# nrf7120E_enga_application register map
Vendor: Nordic Semiconductor; Series: nrf71; File version: 1
CPU: CM33 r0p4, little endian, MPU, FPU, 3 interrupt priority bits, 270 interrupts, 4 SAU regions
Registers are 32-bit, read-write, reset 0x0 unless marked. A register's access mark holds for its fields unless they carry their own. Offsets are from the block's base; [hi:lo] are bit positions; lines under a group give offsets from that group; {n}, {i} and the like mark numbered series; 'fields as' and 'values as' point back to an identical list.

## BELLBOARD_NS — BELLBOARD APB registers
Base 0x40078000
{0x0+4i} TASKS_TRIGGER[{i}] (i=0..3) wo — Description collection: Task TRIGGER[n]
  [0] TASKS_TRIGGER — Task TRIGGER[n]
    1=Trigger task
{0x100+4i} EVENTS_TRIGGERED[{i}] (i=0..3) — Description collection: Event TRIGGERED[n]
  [0] EVENTS_TRIGGERED — Event TRIGGERED[n]
    0=NotGenerated (Event not generated); 1=Generated (Event generated)
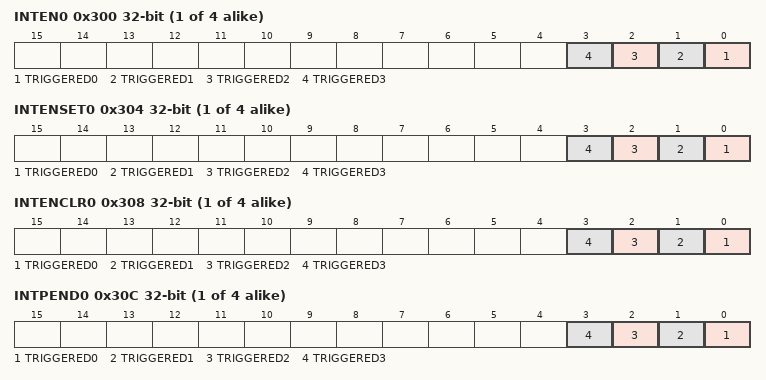
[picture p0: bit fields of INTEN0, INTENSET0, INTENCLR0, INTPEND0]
{0x300+0x10*i} INTEN{i} (i=0..3) — Enable or disable interrupt
  [all] fields
    0=Disabled; 1=Enabled
  [n] TRIGGERED{n} (n=0..3) — Enable or disable interrupt for event TRIGGERED[{n}]
{0x304+0x10*i} INTENSET{i} (i=0..3) — Enable interrupt
  [all] fields
    on read: 0=Disabled (Read: Disabled); 1=Enabled (Read: Enabled) | on write: 1=Set (Enable)
  [n] TRIGGERED{n} write-1-sets (n=0..3) — Write '1' to enable interrupt for event TRIGGERED[{n}]
{0x308+0x10*i} INTENCLR{i} (i=0..3) — Disable interrupt
  [all] fields
    on read: 0=Disabled (Read: Disabled); 1=Enabled (Read: Enabled) | on write: 1=Clear (Disable)
  [n] TRIGGERED{n} write-1-clears (n=0..3) — Write '1' to disable interrupt for event TRIGGERED[{n}]
{0x30C+0x10*i} INTPEND{i} ro (i=0..3) — Pending interrupts
  [all] fields
    on read: 0=NotPending (Read: Not pending); 1=Pending (Read: Pending)
  [n] TRIGGERED{n} (n=0..3) — Read pending status of interrupt for event TRIGGERED[{n}]

## GLOBAL_MEMCONF_NS — Memory configuration 0
Base 0x400CF000
Same registers: GLOBAL_MEMCONF_S 0x500CF000
{0x500+0x10*i} POWER[{i}] (i=0..1) group — Unspecified
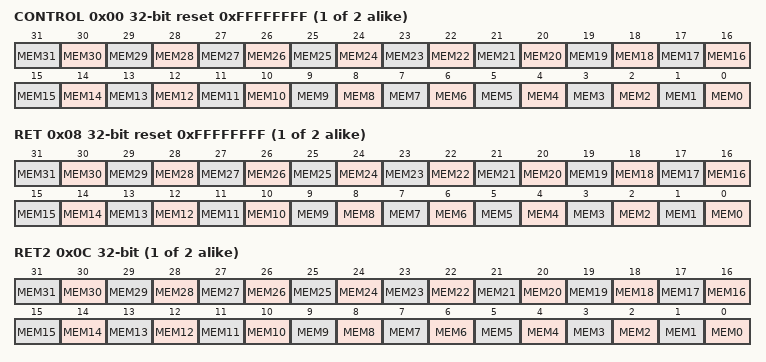
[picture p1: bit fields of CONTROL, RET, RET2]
  0x00 CONTROL reset 0xFFFFFFFF — Description cluster: Control memory block power.
    [all] fields
      0=Off (Power down, not retained); 1=On (Power up, retained)
    [n] MEM{n} (n=0..31) — Keep the memory block MEM[{n}] on or off when in System ON mode.
  0x08 RET reset 0xFFFFFFFF — Description cluster: RAM retention for RAM [n].
    [all] fields
      0=Off (Retention off); 1=On (Retention on)
    [n] MEM{n} (n=0..31) — Keep the RAM block MEM[{n}] retained when in System OFF mode.
  0x0C RET2 — Description cluster: RAM retention for the second bank in the RAM block
    [all] fields
      0=Off (Retention off); 1=On (Retention on)
    [n] MEM{n} (n=0..31) — Keep the second bank in RAM block MEM[{n}] retained when in System OFF mode.

## GLOBAL_TEMP_NS — Temperature Sensor 0
Base 0x400D7000
Same registers: GLOBAL_TEMP_S 0x500D7000
0x00 TASKS_START wo — Start temperature measurement
  [0] TASKS_START
    1=Trigger task
0x04 TASKS_STOP wo — Stop temperature measurement
  [0] TASKS_STOP
    1=Trigger task
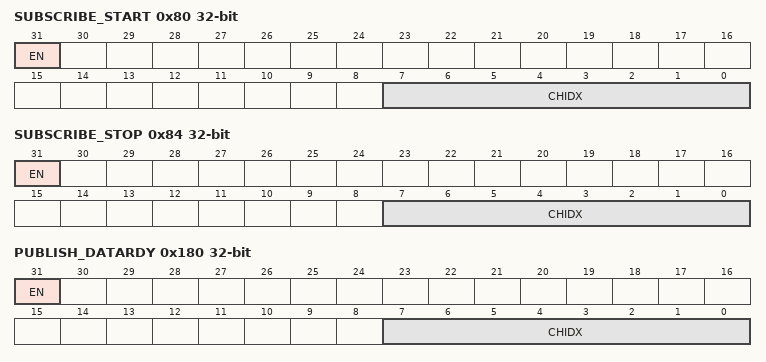
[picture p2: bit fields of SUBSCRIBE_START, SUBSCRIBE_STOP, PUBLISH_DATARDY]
0x80 SUBSCRIBE_START — Subscribe configuration for task START
  [31] EN
    0=Disabled (Disable subscription); 1=Enabled (Enable subscription)
  [7:0] CHIDX — DPPI channel that task START will subscribe to
0x84 SUBSCRIBE_STOP — Subscribe configuration for task STOP
  [31] EN
    values as SUBSCRIBE_START.EN
  [7:0] CHIDX — DPPI channel that task STOP will subscribe to
0x100 EVENTS_DATARDY — Temperature measurement complete, data ready
  [0] EVENTS_DATARDY
    0=NotGenerated (Event not generated); 1=Generated (Event generated)
0x180 PUBLISH_DATARDY — Publish configuration for event DATARDY
  [31] EN
    0=Disabled (Disable publishing); 1=Enabled (Enable publishing)
  [7:0] CHIDX — DPPI channel that event DATARDY will publish to
0x304 INTENSET — Enable interrupt
  [0] DATARDY write-1-sets — Write '1' to enable interrupt for event DATARDY
    on read: 0=Disabled (Read: Disabled); 1=Enabled (Read: Enabled) | on write: 1=Set (Enable)
0x308 INTENCLR — Disable interrupt
  [0] DATARDY write-1-clears — Write '1' to disable interrupt for event DATARDY
    on read: 0=Disabled (Read: Disabled); 1=Enabled (Read: Enabled) | on write: 1=Clear (Disable)
0x508 TEMP ro — Temperature in degC (0.25deg steps)
0x520 A0 reset 0x276 — Slope of 1st piece wise linear function
  [11:0] A0
0x524 A1 reset 0x324 — Slope of 2nd piece wise linear function
  [11:0] A1
0x528 A2 reset 0x3AB — Slope of 3rd piece wise linear function
  [11:0] A2
0x52C A3 reset 0x453 — Slope of 4th piece wise linear function
  [11:0] A3
0x530 A4 reset 0x49B — Slope of 5th piece wise linear function
  [11:0] A4
0x534 A5 reset 0x550 — Slope of 6th piece wise linear function
  [11:0] A5
0x538 A6 reset 0x67E — Slope of 7th piece wise linear function
  [11:0] A6
0x540 B0 reset 0xFA6 — y-intercept of 1st piece wise linear function
  [11:0] B0
0x544 B1 reset 0xF35 — y-intercept of 2nd piece wise linear function
  [11:0] B1
0x548 B2 reset 0xFAA — y-intercept of 3rd piece wise linear function
  [11:0] B2
0x54C B3 reset 0x7E — y-intercept of 4th piece wise linear function
  [11:0] B3
0x550 B4 reset 0xEA — y-intercept of 5th piece wise linear function
  [11:0] B4
0x554 B5 reset 0x1ED — y-intercept of 6th piece wise linear function
  [11:0] B5
0x558 B6 reset 0x378 — y-intercept of 7th piece wise linear function
  [11:0] B6
0x560 T0 reset 0xED — End point of 1st piece wise linear function
  [7:0] T0
0x564 T1 reset 0x13 — End point of 2nd piece wise linear function
  [7:0] T1
0x568 T2 reset 0x29 — End point of 3rd piece wise linear function
  [7:0] T2
0x56C T3 reset 0x3C — End point of 4th piece wise linear function
  [7:0] T3
0x570 T4 reset 0x44 — End point of 5th piece wise linear function
  [7:0] T4
0x574 T5 reset 0x53 — End point of 6th piece wise linear function
  [7:0] T5
